# SF32LB57x register map
File version: 1.0
CPU: CM33 r0p1, little endian, MPU, FPU, 3 interrupt priority bits
Registers are 32-bit, read-write, reset 0x0 unless marked. A register's access mark holds for its fields unless they carry their own. Offsets are from the block's base; [hi:lo] are bit positions; {n}, {i} and the like mark numbered series; 'fields as' and 'values as' point back to an identical list.

## RTC
Base 0x500CB000
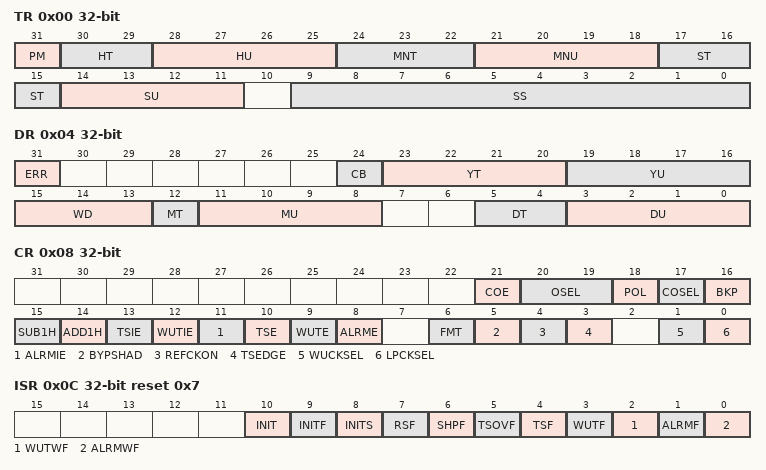
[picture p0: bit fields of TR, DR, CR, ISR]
0x00 TR — Time Register
  [31] PM, [30:29] HT, [28:25] HU, [24:22] MNT, [21:18] MNU, [17:15] ST, [14:11] SU, [9:0] SS
0x04 DR — Date Register
  [31] ERR
  [24] CB — century bit, 0 - 2000s, 1 - 1900s/2100s
  [23:20] YT
  [19:16] YU
  [15:13] WD
  [12] MT
  [11:8] MU
  [5:4] DT
  [3:0] DU
0x08 CR — Control Register
  [21] COE
  [20:19] OSEL
  [18] POL
  [17] COSEL
  [16] BKP
  [15] SUB1H
  [14] ADD1H
  [13] TSIE
  [12] WUTIE
  [11] ALRMIE
  [10] TSE
  [9] WUTE
  [8] ALRME
  [6] FMT
  [5] BYPSHAD
  [4] REFCKON
  [3] TSEDGE
  [1] WUCKSEL
  [0] LPCKSEL — 0 - LRC10; 1 - LXT32
0x0C ISR reset 0x7 — Initialization and Status Register
  [10] INIT, [9] INITF, [8] INITS, [7] RSF, [6] SHPF, [5] TSOVF, [4] TSF, [3] WUTF, [2] WUTWF, [1] ALRMF, [0] ALRMWF
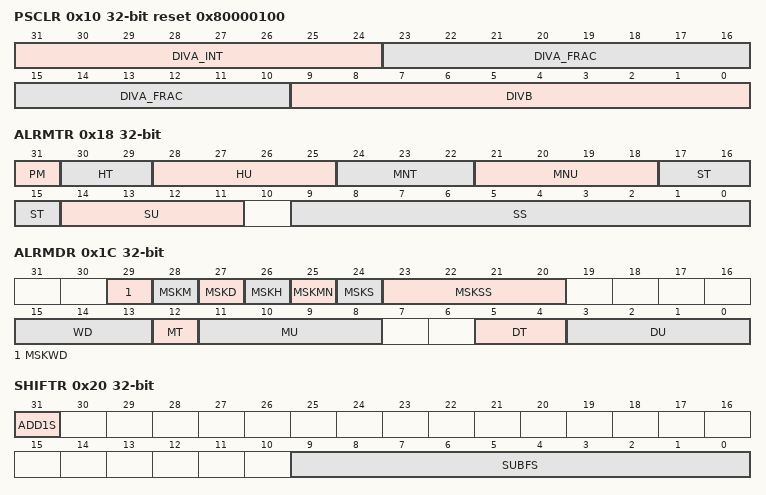
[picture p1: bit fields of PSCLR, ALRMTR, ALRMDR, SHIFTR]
0x10 PSCLR reset 0x80000100 — Prescaler Register
  [31:24] DIVA_INT, [23:10] DIVA_FRAC, [9:0] DIVB
0x14 WUTR — Wakeup Timer Register
  [17:0] WUT
0x18 ALRMTR — Alarm Time Register
  fields as TR
0x1C ALRMDR — Alarm Date Register
  [29] MSKWD, [28] MSKM, [27] MSKD, [26] MSKH, [25] MSKMN, [24] MSKS, [23:20] MSKSS, [15:13] WD, [12] MT, [11:8] MU, [5:4] DT, [3:0] DU
0x20 SHIFTR — Shift Control Register
  [31] ADD1S, [9:0] SUBFS
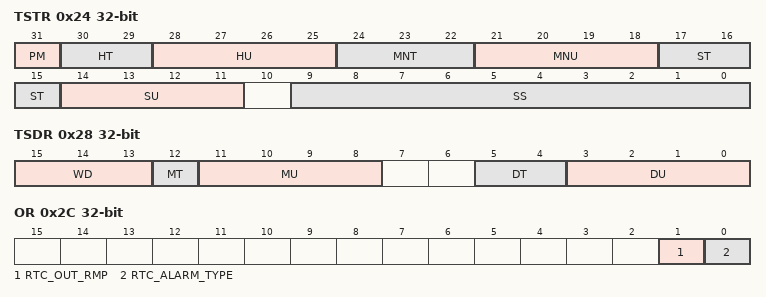
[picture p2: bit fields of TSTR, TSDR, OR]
0x24 TSTR — Timestamp Time Register
  fields as TR
0x28 TSDR — Timestamp Date Register
  [15:13] WD, [12] MT, [11:8] MU, [5:4] DT, [3:0] DU
0x2C OR — Option Register
  [1] RTC_OUT_RMP, [0] RTC_ALARM_TYPE
{0x30+4i} BKP{i}R (i=0..9) — Backup {i} Register
  [31:0] BKP

## LPSYS_RCC
Base 0x40000000
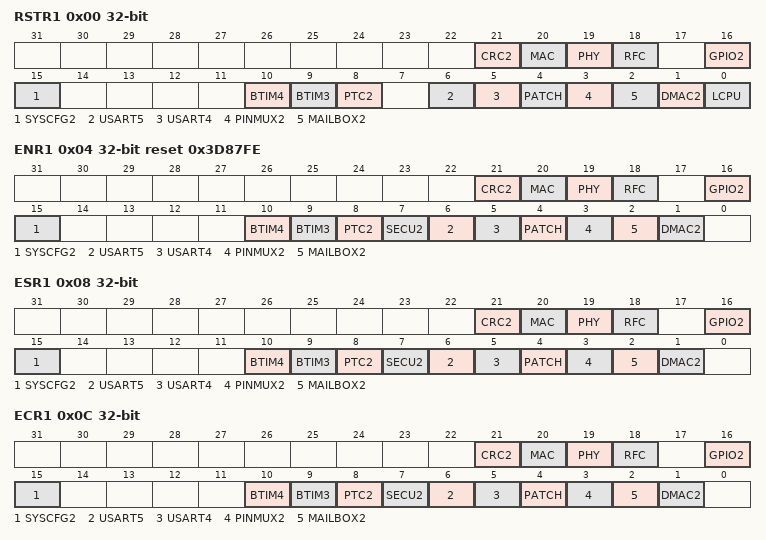
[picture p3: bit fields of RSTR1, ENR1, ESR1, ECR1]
0x00 RSTR1 — Reset Register 1
  [21] CRC2
  [20] MAC
  [19] PHY
  [18] RFC
  [16] GPIO2
  [15] SYSCFG2
  [10] BTIM4
  [9] BTIM3
  [8] PTC2
  [6] USART5
  [5] USART4
  [4] PATCH
  [3] PINMUX2
  [2] MAILBOX2
  [1] DMAC2
  [0] LCPU — 0 - no reset; 1 - reset
0x04 ENR1 reset 0x3D87FE — Enable Register 1
  [21] CRC2
  [20] MAC
  [19] PHY
  [18] RFC
  [16] GPIO2
  [15] SYSCFG2
  [10] BTIM4
  [9] BTIM3
  [8] PTC2
  [7] SECU2
  [6] USART5
  [5] USART4
  [4] PATCH
  [3] PINMUX2
  [2] MAILBOX2
  [1] DMAC2 — 0 - disabled; 1 - enabled
0x08 ESR1 — Enable Set Register 1
  [21] CRC2
  [20] MAC
  [19] PHY
  [18] RFC
  [16] GPIO2
  [15] SYSCFG2
  [10] BTIM4
  [9] BTIM3
  [8] PTC2
  [7] SECU2
  [6] USART5
  [5] USART4
  [4] PATCH
  [3] PINMUX2
  [2] MAILBOX2
  [1] DMAC2 — write 1 to set module enable, write 0 has no effect
0x0C ECR1 — Enable Clear Register 1
  [21] CRC2
  [20] MAC
  [19] PHY
  [18] RFC
  [16] GPIO2
  [15] SYSCFG2
  [10] BTIM4
  [9] BTIM3
  [8] PTC2
  [7] SECU2
  [6] USART5
  [5] USART4
  [4] PATCH
  [3] PINMUX2
  [2] MAILBOX2
  [1] DMAC2 — write 1 to clear module enable, write 0 has no effect
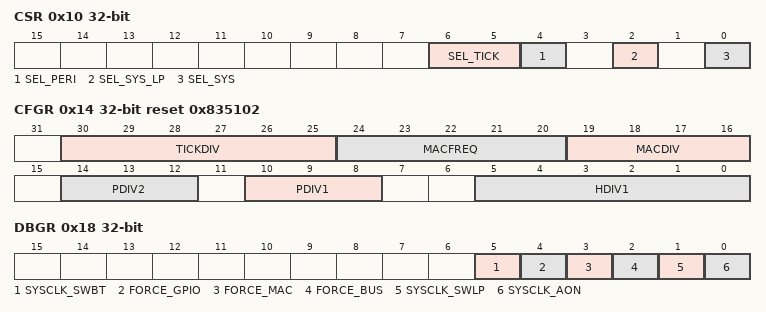
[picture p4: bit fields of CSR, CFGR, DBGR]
0x10 CSR — Clock Select Register
  [6:5] SEL_TICK — 0 - CLK_LP; 1 - RSVD; 2 - HRC48; 3 - HXT48
  [4] SEL_PERI — 0 - HRC48; 1 - HXT48 (including USART)
  [2] SEL_SYS_LP — 0- SYSCLK; 1 - CLK_LP
  [0] SEL_SYS — 0 - HRC48; 1 - HXT48
0x14 CFGR reset 0x835102 — Clock Configuration Register
  [30:25] TICKDIV — SYSTICK REF = PERI_CLK / TICKDIV
  [24:20] MACFREQ — clock frequency of BLE MAC master clock
  [19:16] MACDIV — MACCLK = HCLK / MACDIV
  [14:12] PDIV2 — PCLK2 = HCLK / (2^PDIV2), by default divided by 32
  [10:8] PDIV1 — PCLK1 = HCLK / (2^PDIV1), by default divided by 2
  [5:0] HDIV1 — HCLK = 48M (RC or XTAL) / HDIV
0x18 DBGR — Debug Register
  [5] SYSCLK_SWBT — If set to 1, system clock will: switch from HRC to HXT when bt active; switch from HXT to HRC when bt sleep; do not switch if DLB96 or HRC1M selected
  [4] FORCE_GPIO — If set to 1, GPIO will not switch to LPCLK during LS/DS
  [3] FORCE_MAC — Force MAC clock on
  [2] FORCE_BUS — Force bus clock on
  [1] SYSCLK_SWLP — Switch system clock to CLK_LP during LS/DS. This option will overwrite SYSCLK_AON
  [0] SYSCLK_AON — Force system clock always on, regardless of the SYS_CLK_EN signal during LS/DS

## LPSYS_PINMUX
Base 0x40003000
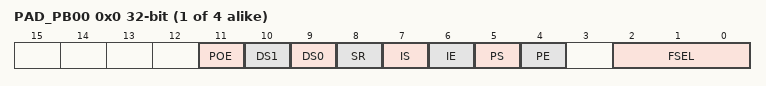
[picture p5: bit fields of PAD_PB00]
{0x0+4i} PAD_PB{i:02} (i=0..3)
  [11] POE — Reserved. Always set to logic LOW
  [10] DS1 — Drive Select 1. Used to select output drive strength
  [9] DS0 — Drive Select 0. Used to select output drive strength
  [8] SR — Slew Rate. Logic HIGH selects slow slew rate, logic LOW selects fast slew rate
  [7] IS — Input Select. Logic LOW selects CMOS input, logic HIGH selects Schmitt input
  [6] IE — Input Enable. Logic HIGH enables the input buffer
  [5] PS — Pull Select. Logic HIGH selects pull-up, logic LOW select pull-down
  [4] PE — Pull Enable. Logic HIGH enables week pull device
  [2:0] FSEL — Function Select

## PATCH
Base 0x40004000
{0x0+4i} CH{i} reset 0x7FFFC (i=0..31) — Channel {i} address
  [18:2] ADDR — bit [18:2] of ROM address need to be patched. bit [1:0] are fixed to 0
0x80 CER — Channel enable register
  [31:0] CE — enable for channel 31~0 When enabled, ROM read to corresponding channel address will be patched, return value will be the patched value
0x84 CSR — Channel select register for data read/write
  [31:0] CS — channel one-hot select for data read/write. Before write/read channel data, set correspond channel select bit. Caution that patch will not work correctly until all select bit cleared.
0x88 CDR — Channel data register
  [31:0] DATA — channel data value in patch table. When read, return channel data in patch table When write, update channel data in patch table
0x90 IER — Interrupt enable register
  [31:0] CIE — enable for channel 31~0 interrupt When enabled, channel interrupt will occur when reading to corresponding channel address
0x94 ISR — Interrupt status register
  [31:0] CIS — channel 31~0 interrupt status
0x98 ICR — Interrupt clear register
  [31:0] CIC — generate clear pulse for channel 31~0 interrupt
0x9C VER — Revision ID register
  [31:0] ID — Revision ID

## LPSYS_CFG
Base 0x4000F000
0x00 SYSCR — System Configure Register
  [0] LDO_VSEL — LDO voltage select. 0 - 0.9V, 1 - 1.0V
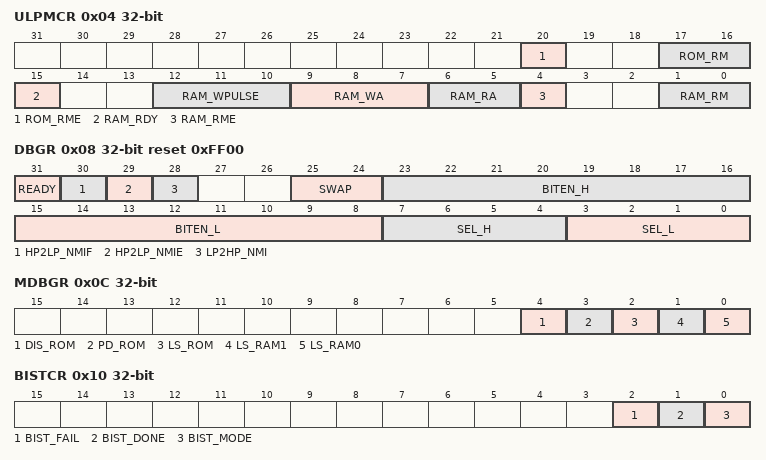
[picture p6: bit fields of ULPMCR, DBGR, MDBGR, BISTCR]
0x04 ULPMCR — Memory Control register
  [20] ROM_RME, [17:16] ROM_RM, [15] RAM_RDY, [12:10] RAM_WPULSE, [9:7] RAM_WA, [6:5] RAM_RA, [4] RAM_RME, [1:0] RAM_RM
0x08 DBGR reset 0xFF00 — Debug Register
  [31] READY — used for software debug to indicate lcpu is ready
  [30] HP2LP_NMIF — HP2LP NMI interrupt flag
  [29] HP2LP_NMIE — HP2LP NMI interrupt enable
  [28] LP2HP_NMI — set 1 to send NMI interrupt to HCPU
  [25:24] SWAP — swap debug out data H/L bytes
  [23:16] BITEN_H — bit enable for debug data higher byte, active high
  [15:8] BITEN_L — bit enable for debug data lower byte, active high
  [7:4] SEL_H — select higher byte of debug data
  [3:0] SEL_L — select lower byte of debug data
0x0C MDBGR — Memory Debug Register
  [4] DIS_ROM — Disable ROM during active
  [3] PD_ROM — Power down ROM during deep sleep
  [2] LS_ROM — Force ROM into Light Sleep mode during active
  [1] LS_RAM1
  [0] LS_RAM0 — Force RAM0 into Light Sleep mode during active
0x10 BISTCR — Bist Control Register
  [2] BIST_FAIL — All-in-one BIST fail flag
  [1] BIST_DONE — All-in-one BIST done flag
  [0] BIST_MODE — Set 1 to enable BIST mode
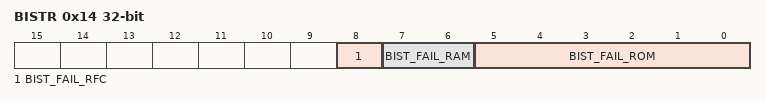
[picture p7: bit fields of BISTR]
0x14 BISTR — Bist Result Register
  [8] BIST_FAIL_RFC, [7:6] BIST_FAIL_RAM, [5:0] BIST_FAIL_ROM
{0x18+4i} ROMCR{i} (i=0..5) — ROM Compare Register {i}
  [31:0] SIG
